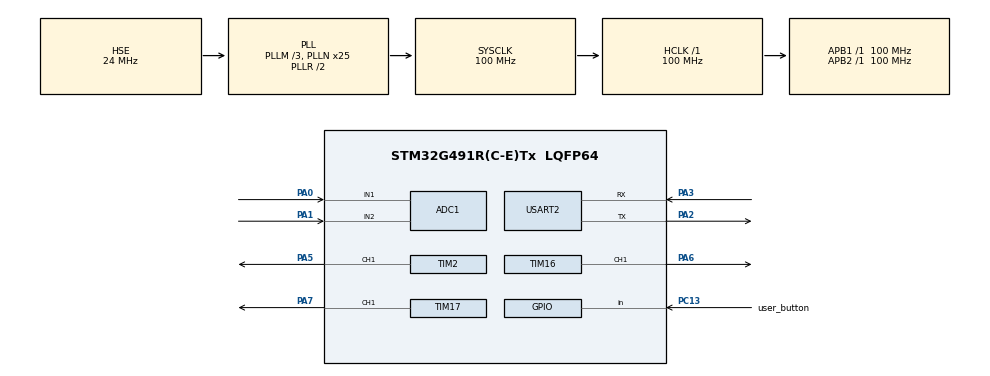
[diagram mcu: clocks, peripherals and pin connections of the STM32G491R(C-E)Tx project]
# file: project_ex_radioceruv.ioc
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ADC1.Channel-3\#ChannelRegularConversion=ADC_CHANNEL_1
ADC1.Channel-4\#ChannelRegularConversion=ADC_CHANNEL_2
ADC1.ClockPrescaler=ADC_CLOCK_SYNC_PCLK_DIV4
ADC1.ContinuousConvMode=ENABLE
ADC1.DMAContinuousRequests=ENABLE
ADC1.DataAlign=ADC_DATAALIGN_RIGHT
ADC1.EOCSelection=ADC_EOC_SINGLE_CONV
ADC1.EnableAnalogWatchDog3=false
ADC1.NbrOfConversion=2
ADC1.NbrOfConversionFlag=1
ADC1.OffsetNumber-3\#ChannelRegularConversion=ADC_OFFSET_NONE
ADC1.OffsetNumber-4\#ChannelRegularConversion=ADC_OFFSET_NONE
ADC1.Overrun=ADC_OVR_DATA_OVERWRITTEN
ADC1.OversamplingMode=DISABLE
ADC1.Rank-3\#ChannelRegularConversion=1
ADC1.Rank-4\#ChannelRegularConversion=2
ADC1.SamplingTime-3\#ChannelRegularConversion=ADC_SAMPLETIME_47CYCLES_5
ADC1.SamplingTime-4\#ChannelRegularConversion=ADC_SAMPLETIME_47CYCLES_5
ADC1.master=1
Dma.ADC1.0.Direction=DMA_PERIPH_TO_MEMORY
Dma.ADC1.0.EventEnable=DISABLE
Dma.ADC1.0.Instance=DMA1_Channel1
Dma.ADC1.0.MemDataAlignment=DMA_MDATAALIGN_HALFWORD
Dma.ADC1.0.MemInc=DMA_MINC_ENABLE
Dma.ADC1.0.Mode=DMA_CIRCULAR
Dma.ADC1.0.PeriphDataAlignment=DMA_PDATAALIGN_HALFWORD
Dma.ADC1.0.PeriphInc=DMA_PINC_DISABLE
Dma.ADC1.0.Polarity=HAL_DMAMUX_REQ_GEN_RISING
Dma.ADC1.0.Priority=DMA_PRIORITY_LOW
Dma.ADC1.0.RequestNumber=1
Dma.ADC1.0.SignalID=NONE
Dma.ADC1.0.SyncEnable=DISABLE
Dma.ADC1.0.SyncPolarity=HAL_DMAMUX_SYNC_NO_EVENT
Dma.ADC1.0.SyncRequestNumber=1
Dma.ADC1.0.SyncSignalID=NONE
Dma.Request0=ADC1
Mcu.Family=STM32G4
Mcu.Name=STM32G491R(C-E)Tx
Mcu.Package=LQFP64
NVIC.DMA1_Channel1_IRQn=true\:0\:0\:false\:false\:true\:false\:true\:true
NVIC.PriorityGroup=NVIC_PRIORITYGROUP_4
PA0.Mode=IN1-Single-Ended
PA0.Signal=ADC1_IN1
PA1.Mode=IN2-Single-Ended
PA1.Signal=ADC1_IN2
PA2.Mode=Asynchronous
PA2.Signal=USART2_TX
PA3.Mode=Asynchronous
PA3.Signal=USART2_RX
PA5.Signal=S_TIM2_CH1
PA6.Signal=S_TIM16_CH1
PA7.Signal=S_TIM17_CH1
PC13.GPIO_Label=user_button
PC13.Signal=GPIO_Input
PF0-OSC_IN.Mode=HSE-External-Oscillator
PF0-OSC_IN.Signal=RCC_OSC_IN
PF1-OSC_OUT.Mode=HSE-External-Oscillator
PF1-OSC_OUT.Signal=RCC_OSC_OUT
ProjectManager.HeapSize=0x200
ProjectManager.StackSize=0x400
ProjectManager.TargetToolchain=STM32CubeIDE
RCC.ADC12Freq_Value=100000000
RCC.ADC345Freq_Value=100000000
RCC.AHBFreq_Value=100000000
RCC.APB1Freq_Value=100000000
RCC.APB1TimFreq_Value=100000000
RCC.APB2Freq_Value=100000000
RCC.APB2TimFreq_Value=100000000
RCC.CortexFreq_Value=100000000
RCC.EXTERNAL_CLOCK_VALUE=12288000
RCC.HCLKFreq_Value=100000000
RCC.HSE_VALUE=24000000
RCC.HSI48_VALUE=48000000
RCC.HSI_VALUE=16000000
RCC.LSE_VALUE=32768
RCC.PLLM=RCC_PLLM_DIV3
RCC.PLLN=25
RCC.PLLSourceVirtual=RCC_PLLSOURCE_HSE
RCC.SYSCLKFreq_VALUE=100000000
RCC.SYSCLKSource=RCC_SYSCLKSOURCE_PLLCLK
RCC.VCOOutputFreq_Value=200000000
SH.S_TIM16_CH1.0=TIM16_CH1,PWM Generation1 CH1
SH.S_TIM17_CH1.0=TIM17_CH1,PWM Generation1 CH1
SH.S_TIM2_CH1.0=TIM2_CH1,PWM Generation1 CH1
TIM16.Channel=TIM_CHANNEL_1
TIM16.PeriodNoDither=255
TIM16.Prescaler=19
TIM17.Channel=TIM_CHANNEL_1
TIM17.PeriodNoDither=255
TIM17.Prescaler=19
TIM2.Channel-PWM\ Generation1\ CH1=TIM_CHANNEL_1
TIM2.PeriodNoDither=255
TIM2.Prescaler=19
USART2.VirtualMode-Asynchronous=VM_ASYNC
VP_SYS_VS_DBSignals.Mode=DisableDeadBatterySignals
VP_TIM16_VS_ClockSourceINT.Mode=Enable_Timer
VP_TIM17_VS_ClockSourceINT.Mode=Enable_Timer
VP_TIM2_VS_ClockSourceINT.Mode=Internal
board=custom

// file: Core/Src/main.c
/* USER CODE BEGIN Header */
/**
  ******************************************************************************
  * @file           : main.c
  * @brief          : Main program body
  ******************************************************************************
  * @attention
  *
  * Copyright (c) 2026 STMicroelectronics.
  * All rights reserved.
  *
  * This software is licensed under terms that can be found in the LICENSE file
  * in the root directory of this software component.
  * If no LICENSE file comes with this software, it is provided AS-IS.
  *
  ******************************************************************************
  */
/* USER CODE END Header */
#include "main.h"

/* USER CODE BEGIN Includes */

#include "test_liba.h"
#include "struct.h"
#include "uart_lib.h"
#include "adc_lib.h"

#define RX_SIZE_BUFFER 32

/* USER CODE END Includes */

ADC_HandleTypeDef hadc1;
DMA_HandleTypeDef hdma_adc1;

TIM_HandleTypeDef htim2;
TIM_HandleTypeDef htim16;
TIM_HandleTypeDef htim17;

UART_HandleTypeDef huart2;

void SystemClock_Config(void);
static void MX_GPIO_Init(void);
static void MX_DMA_Init(void);
static void MX_USART2_UART_Init(void);
static void MX_TIM2_Init(void);
static void MX_TIM16_Init(void);
static void MX_TIM17_Init(void);
static void MX_ADC1_Init(void);

int main(void)
{

  /* MCU Configuration--------------------------------------------------------*/

  /* Reset of all peripherals, Initializes the Flash interface and the Systick. */
  HAL_Init();

  /* Configure the system clock */
  SystemClock_Config();

  /* Initialize all configured peripherals */
  MX_GPIO_Init();
  MX_DMA_Init();
  MX_USART2_UART_Init();
  MX_TIM2_Init();
  MX_TIM16_Init();
  MX_TIM17_Init();
  MX_ADC1_Init();
  /* USER CODE BEGIN 2 */

  initPWM();

  initADC();

  LedPWMStatus all = {0, 0, 0};
 // LedPWMStatus ser = {0, 125, 255};
  //LedPWMStatus red_ser = {20, 255, 0};

  uartPrintln("Hello, world");
  HAL_Delay(STANDART_DEL);

  char rxBuffer[RX_SIZE_BUFFER];

  // 1. Буфер під 2 канали DMA (глобальний або static)
  //volatile uint16_t adc_buf[2] = {0};

  // 2. Калібрування АЦП (викликати один раз перед стартом)
  //HAL_ADCEx_Calibration_Start(&hadc1, ADC_SINGLE_ENDED);

  // 3. Запуск безперервного зчитування в циклічний DMA-буфер (викликати один раз)
  //HAL_ADC_Start_DMA(&hadc1, (uint32_t *)adc_buf, 2);

  /* USER CODE END 2 */

  /* Infinite loop */
  while (1)
  {

	  printSides();
	  HAL_Delay(1500);

  }
}

void SystemClock_Config(void)
{
  RCC_OscInitTypeDef RCC_OscInitStruct = {0};
  RCC_ClkInitTypeDef RCC_ClkInitStruct = {0};

  /** Configure the main internal regulator output voltage
  */
  HAL_PWREx_ControlVoltageScaling(PWR_REGULATOR_VOLTAGE_SCALE1);

  /** Initializes the RCC Oscillators according to the specified parameters
  * in the RCC_OscInitTypeDef structure.
  */
  RCC_OscInitStruct.OscillatorType = RCC_OSCILLATORTYPE_HSE;
  RCC_OscInitStruct.HSEState = RCC_HSE_ON;
  RCC_OscInitStruct.PLL.PLLState = RCC_PLL_ON;
  RCC_OscInitStruct.PLL.PLLSource = RCC_PLLSOURCE_HSE;
  RCC_OscInitStruct.PLL.PLLM = RCC_PLLM_DIV3;
  RCC_OscInitStruct.PLL.PLLN = 25;
  RCC_OscInitStruct.PLL.PLLP = RCC_PLLP_DIV2;
  RCC_OscInitStruct.PLL.PLLQ = RCC_PLLQ_DIV2;
  RCC_OscInitStruct.PLL.PLLR = RCC_PLLR_DIV2;
  if (HAL_RCC_OscConfig(&RCC_OscInitStruct) != HAL_OK)
  {
    Error_Handler();
  }

  /** Initializes the CPU, AHB and APB buses clocks
  */
  RCC_ClkInitStruct.ClockType = RCC_CLOCKTYPE_HCLK|RCC_CLOCKTYPE_SYSCLK
                              |RCC_CLOCKTYPE_PCLK1|RCC_CLOCKTYPE_PCLK2;
  RCC_ClkInitStruct.SYSCLKSource = RCC_SYSCLKSOURCE_PLLCLK;
  RCC_ClkInitStruct.AHBCLKDivider = RCC_SYSCLK_DIV1;
  RCC_ClkInitStruct.APB1CLKDivider = RCC_HCLK_DIV1;
  RCC_ClkInitStruct.APB2CLKDivider = RCC_HCLK_DIV1;

  if (HAL_RCC_ClockConfig(&RCC_ClkInitStruct, FLASH_LATENCY_3) != HAL_OK)
  {
    Error_Handler();
  }
}

static void MX_ADC1_Init(void)
{

  ADC_MultiModeTypeDef multimode = {0};
  ADC_ChannelConfTypeDef sConfig = {0};

  /** Common config
  */
  hadc1.Instance = ADC1;
  hadc1.Init.ClockPrescaler = ADC_CLOCK_SYNC_PCLK_DIV4;
  hadc1.Init.Resolution = ADC_RESOLUTION_12B;
  hadc1.Init.DataAlign = ADC_DATAALIGN_RIGHT;
  hadc1.Init.GainCompensation = 0;
  hadc1.Init.ScanConvMode = ADC_SCAN_ENABLE;
  hadc1.Init.EOCSelection = ADC_EOC_SINGLE_CONV;
  hadc1.Init.LowPowerAutoWait = DISABLE;
  hadc1.Init.ContinuousConvMode = ENABLE;
  hadc1.Init.NbrOfConversion = 2;
  hadc1.Init.DiscontinuousConvMode = DISABLE;
  hadc1.Init.ExternalTrigConv = ADC_SOFTWARE_START;
  hadc1.Init.ExternalTrigConvEdge = ADC_EXTERNALTRIGCONVEDGE_NONE;
  hadc1.Init.DMAContinuousRequests = ENABLE;
  hadc1.Init.Overrun = ADC_OVR_DATA_OVERWRITTEN;
  hadc1.Init.OversamplingMode = DISABLE;
  if (HAL_ADC_Init(&hadc1) != HAL_OK)
  {
    Error_Handler();
  }

  /** Configure the ADC multi-mode
  */
  multimode.Mode = ADC_MODE_INDEPENDENT;
  if (HAL_ADCEx_MultiModeConfigChannel(&hadc1, &multimode) != HAL_OK)
  {
    Error_Handler();
  }

  /** Configure Regular Channel
  */
  sConfig.Channel = ADC_CHANNEL_1;
  sConfig.Rank = ADC_REGULAR_RANK_1;
  sConfig.SamplingTime = ADC_SAMPLETIME_47CYCLES_5;
  sConfig.SingleDiff = ADC_SINGLE_ENDED;
  sConfig.OffsetNumber = ADC_OFFSET_NONE;
  sConfig.Offset = 0;
  if (HAL_ADC_ConfigChannel(&hadc1, &sConfig) != HAL_OK)
  {
    Error_Handler();
  }

  /** Configure Regular Channel
  */
  sConfig.Channel = ADC_CHANNEL_2;
  sConfig.Rank = ADC_REGULAR_RANK_2;
  if (HAL_ADC_ConfigChannel(&hadc1, &sConfig) != HAL_OK)
  {
    Error_Handler();
  }

}

static void MX_TIM2_Init(void)
{

  TIM_ClockConfigTypeDef sClockSourceConfig = {0};
  TIM_MasterConfigTypeDef sMasterConfig = {0};
  TIM_OC_InitTypeDef sConfigOC = {0};

  htim2.Instance = TIM2;
  htim2.Init.Prescaler = 19;
  htim2.Init.CounterMode = TIM_COUNTERMODE_UP;
  htim2.Init.Period = 255;
  htim2.Init.ClockDivision = TIM_CLOCKDIVISION_DIV1;
  htim2.Init.AutoReloadPreload = TIM_AUTORELOAD_PRELOAD_DISABLE;
  if (HAL_TIM_Base_Init(&htim2) != HAL_OK)
  {
    Error_Handler();
  }
  sClockSourceConfig.ClockSource = TIM_CLOCKSOURCE_INTERNAL;
  if (HAL_TIM_ConfigClockSource(&htim2, &sClockSourceConfig) != HAL_OK)
  {
    Error_Handler();
  }
  if (HAL_TIM_PWM_Init(&htim2) != HAL_OK)
  {
    Error_Handler();
  }
  sMasterConfig.MasterOutputTrigger = TIM_TRGO_RESET;
  sMasterConfig.MasterSlaveMode = TIM_MASTERSLAVEMODE_DISABLE;
  if (HAL_TIMEx_MasterConfigSynchronization(&htim2, &sMasterConfig) != HAL_OK)
  {
    Error_Handler();
  }
  sConfigOC.OCMode = TIM_OCMODE_PWM1;
  sConfigOC.Pulse = 0;
  sConfigOC.OCPolarity = TIM_OCPOLARITY_HIGH;
  sConfigOC.OCFastMode = TIM_OCFAST_DISABLE;
  if (HAL_TIM_PWM_ConfigChannel(&htim2, &sConfigOC, TIM_CHANNEL_1) != HAL_OK)
  {
    Error_Handler();
  }
  HAL_TIM_MspPostInit(&htim2);

}

static void MX_TIM16_Init(void)
{

  TIM_OC_InitTypeDef sConfigOC = {0};
  TIM_BreakDeadTimeConfigTypeDef sBreakDeadTimeConfig = {0};

  htim16.Instance = TIM16;
  htim16.Init.Prescaler = 19;
  htim16.Init.CounterMode = TIM_COUNTERMODE_UP;
  htim16.Init.Period = 255;
  htim16.Init.ClockDivision = TIM_CLOCKDIVISION_DIV1;
  htim16.Init.RepetitionCounter = 0;
  htim16.Init.AutoReloadPreload = TIM_AUTORELOAD_PRELOAD_DISABLE;
  if (HAL_TIM_Base_Init(&htim16) != HAL_OK)
  {
    Error_Handler();
  }
  if (HAL_TIM_PWM_Init(&htim16) != HAL_OK)
  {
    Error_Handler();
  }
  sConfigOC.OCMode = TIM_OCMODE_PWM1;
  sConfigOC.Pulse = 0;
  sConfigOC.OCPolarity = TIM_OCPOLARITY_HIGH;
  sConfigOC.OCNPolarity = TIM_OCNPOLARITY_HIGH;
  sConfigOC.OCFastMode = TIM_OCFAST_DISABLE;
  sConfigOC.OCIdleState = TIM_OCIDLESTATE_RESET;
  sConfigOC.OCNIdleState = TIM_OCNIDLESTATE_RESET;
  if (HAL_TIM_PWM_ConfigChannel(&htim16, &sConfigOC, TIM_CHANNEL_1) != HAL_OK)
  {
    Error_Handler();
  }
  sBreakDeadTimeConfig.OffStateRunMode = TIM_OSSR_DISABLE;
  sBreakDeadTimeConfig.OffStateIDLEMode = TIM_OSSI_DISABLE;
  sBreakDeadTimeConfig.LockLevel = TIM_LOCKLEVEL_OFF;
  sBreakDeadTimeConfig.DeadTime = 0;
  sBreakDeadTimeConfig.BreakState = TIM_BREAK_DISABLE;
  sBreakDeadTimeConfig.BreakPolarity = TIM_BREAKPOLARITY_HIGH;
  sBreakDeadTimeConfig.BreakFilter = 0;
  sBreakDeadTimeConfig.AutomaticOutput = TIM_AUTOMATICOUTPUT_DISABLE;
  if (HAL_TIMEx_ConfigBreakDeadTime(&htim16, &sBreakDeadTimeConfig) != HAL_OK)
  {
    Error_Handler();
  }
  HAL_TIM_MspPostInit(&htim16);

}

static void MX_TIM17_Init(void)
{

  TIM_OC_InitTypeDef sConfigOC = {0};
  TIM_BreakDeadTimeConfigTypeDef sBreakDeadTimeConfig = {0};

  htim17.Instance = TIM17;
  htim17.Init.Prescaler = 19;
  htim17.Init.CounterMode = TIM_COUNTERMODE_UP;
  htim17.Init.Period = 255;
  htim17.Init.ClockDivision = TIM_CLOCKDIVISION_DIV1;
  htim17.Init.RepetitionCounter = 0;
  htim17.Init.AutoReloadPreload = TIM_AUTORELOAD_PRELOAD_DISABLE;
  if (HAL_TIM_Base_Init(&htim17) != HAL_OK)
  {
    Error_Handler();
  }
  if (HAL_TIM_PWM_Init(&htim17) != HAL_OK)
  {
    Error_Handler();
  }
  sConfigOC.OCMode = TIM_OCMODE_PWM1;
  sConfigOC.Pulse = 0;
  sConfigOC.OCPolarity = TIM_OCPOLARITY_HIGH;
  sConfigOC.OCNPolarity = TIM_OCNPOLARITY_HIGH;
  sConfigOC.OCFastMode = TIM_OCFAST_DISABLE;
  sConfigOC.OCIdleState = TIM_OCIDLESTATE_RESET;
  sConfigOC.OCNIdleState = TIM_OCNIDLESTATE_RESET;
  if (HAL_TIM_PWM_ConfigChannel(&htim17, &sConfigOC, TIM_CHANNEL_1) != HAL_OK)
  {
    Error_Handler();
  }
  sBreakDeadTimeConfig.OffStateRunMode = TIM_OSSR_DISABLE;
  sBreakDeadTimeConfig.OffStateIDLEMode = TIM_OSSI_DISABLE;
  sBreakDeadTimeConfig.LockLevel = TIM_LOCKLEVEL_OFF;
  sBreakDeadTimeConfig.DeadTime = 0;
  sBreakDeadTimeConfig.BreakState = TIM_BREAK_DISABLE;
  sBreakDeadTimeConfig.BreakPolarity = TIM_BREAKPOLARITY_HIGH;
  sBreakDeadTimeConfig.BreakFilter = 0;
  sBreakDeadTimeConfig.AutomaticOutput = TIM_AUTOMATICOUTPUT_DISABLE;
  if (HAL_TIMEx_ConfigBreakDeadTime(&htim17, &sBreakDeadTimeConfig) != HAL_OK)
  {
    Error_Handler();
  }
  HAL_TIM_MspPostInit(&htim17);

}

static void MX_USART2_UART_Init(void)
{

  huart2.Instance = USART2;
  huart2.Init.BaudRate = 115200;
  huart2.Init.WordLength = UART_WORDLENGTH_8B;
  huart2.Init.StopBits = UART_STOPBITS_1;
  huart2.Init.Parity = UART_PARITY_NONE;
  huart2.Init.Mode = UART_MODE_TX_RX;
  huart2.Init.HwFlowCtl = UART_HWCONTROL_NONE;
  huart2.Init.OverSampling = UART_OVERSAMPLING_16;
  huart2.Init.OneBitSampling = UART_ONE_BIT_SAMPLE_DISABLE;
  huart2.Init.ClockPrescaler = UART_PRESCALER_DIV1;
  huart2.AdvancedInit.AdvFeatureInit = UART_ADVFEATURE_NO_INIT;
  if (HAL_UART_Init(&huart2) != HAL_OK)
  {
    Error_Handler();
  }
  if (HAL_UARTEx_SetTxFifoThreshold(&huart2, UART_TXFIFO_THRESHOLD_1_8) != HAL_OK)
  {
    Error_Handler();
  }
  if (HAL_UARTEx_SetRxFifoThreshold(&huart2, UART_RXFIFO_THRESHOLD_1_8) != HAL_OK)
  {
    Error_Handler();
  }
  if (HAL_UARTEx_DisableFifoMode(&huart2) != HAL_OK)
  {
    Error_Handler();
  }

}

static void MX_DMA_Init(void)
{

  /* DMA controller clock enable */
  __HAL_RCC_DMAMUX1_CLK_ENABLE();
  __HAL_RCC_DMA1_CLK_ENABLE();

  /* DMA interrupt init */
  /* DMA1_Channel1_IRQn interrupt configuration */
  HAL_NVIC_SetPriority(DMA1_Channel1_IRQn, 0, 0);
  HAL_NVIC_EnableIRQ(DMA1_Channel1_IRQn);

}

static void MX_GPIO_Init(void)
{
  GPIO_InitTypeDef GPIO_InitStruct = {0};

  /* GPIO Ports Clock Enable */
  __HAL_RCC_GPIOC_CLK_ENABLE();
  __HAL_RCC_GPIOF_CLK_ENABLE();
  __HAL_RCC_GPIOA_CLK_ENABLE();

  /*Configure GPIO pin : user_button_Pin */
  GPIO_InitStruct.Pin = user_button_Pin;
  GPIO_InitStruct.Mode = GPIO_MODE_INPUT;
  GPIO_InitStruct.Pull = GPIO_NOPULL;
  HAL_GPIO_Init(user_button_GPIO_Port, &GPIO_InitStruct);

}

void Error_Handler(void)
{
  __disable_irq();
  while (1)
  {
  }
}
